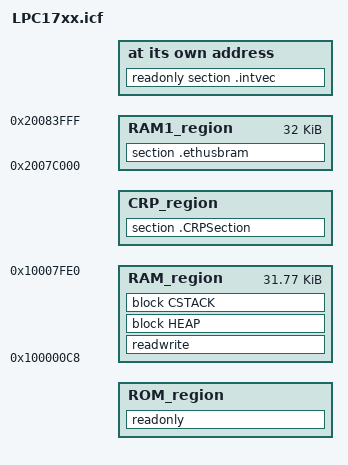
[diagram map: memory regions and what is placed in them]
if (!isdefinedsymbol(MBED_APP_START)) { define symbol MBED_APP_START = 0x00000000; }
if (!isdefinedsymbol(MBED_APP_SIZE)) { define symbol MBED_APP_SIZE = 0x80000; }
/*###ICF### Section handled by ICF editor, don't touch! ****/
/*-Editor annotation file-*/
/* IcfEditorFile="$TOOLKIT_DIR$\config\ide\IcfEditor\cortex_v1_0.xml" */
/*-Specials-*/
define symbol __ICFEDIT_intvec_start__ = MBED_APP_START;
/*-Memory Regions-*/
define symbol __ICFEDIT_region_ROM_start__   = MBED_APP_START;
define symbol __ICFEDIT_region_ROM_end__     = MBED_APP_START + MBED_APP_SIZE - 1;
define symbol __ICFEDIT_region_NVIC_start__   = 0x10000000;
define symbol __ICFEDIT_region_NVIC_end__   = 0x100000C7;
define symbol __ICFEDIT_region_RAM_start__   = 0x100000C8;
define symbol __ICFEDIT_region_RAM_end__     = 0x10007FE0;

/*-Sizes-*/
if (!isdefinedsymbol(MBED_BOOT_STACK_SIZE)) {
    define symbol MBED_BOOT_STACK_SIZE = 0x400;
}

define symbol __ICFEDIT_size_cstack__   = MBED_BOOT_STACK_SIZE;
define symbol __ICFEDIT_size_heap__     = 0x2000;
/**** End of ICF editor section. ###ICF###*/

define symbol __CRP_start__   = MBED_APP_START + 0x000002FC;
define symbol __CRP_end__     = MBED_APP_START + 0x000002FF;

define symbol __RAM1_start__  = 0x2007C000;
define symbol __RAM1_end__    = 0x20083FFF;

define memory mem with size = 4G;
define region ROM_region   = mem:[from __ICFEDIT_region_ROM_start__   to __ICFEDIT_region_ROM_end__] -  mem:[from  __CRP_start__ to __CRP_end__];
define region RAM_region   = mem:[from __ICFEDIT_region_RAM_start__   to __ICFEDIT_region_RAM_end__];
define region CRP_region   = mem:[from __CRP_start__ to __CRP_end__];
define region RAM1_region  = mem:[from __RAM1_start__ to __RAM1_end__];

define block CSTACK    with alignment = 8, size = __ICFEDIT_size_cstack__   { };
define block HEAP      with alignment = 8, size = __ICFEDIT_size_heap__     { };


initialize by copy { readwrite };
do not initialize  { section .noinit };

place at address mem:__ICFEDIT_intvec_start__ { readonly section .intvec };
place in ROM_region   { readonly };
place in RAM_region   { readwrite,
                        block HEAP, block CSTACK };

place in CRP_region  	{ section .CRPSection };
place in RAM1_region	{ section .ethusbram };
